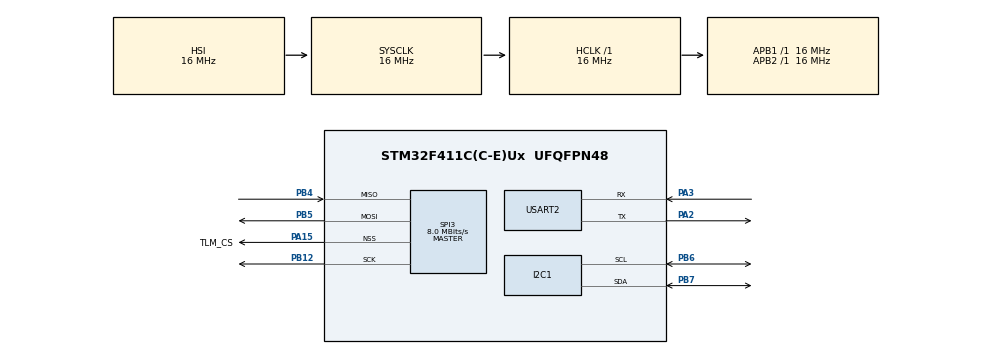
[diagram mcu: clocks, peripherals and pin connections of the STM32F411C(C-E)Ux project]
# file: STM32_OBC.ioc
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Dma.Request0=SPI3_TX
Dma.Request1=SPI3_RX
Dma.SPI3_RX.1.Direction=DMA_PERIPH_TO_MEMORY
Dma.SPI3_RX.1.FIFOMode=DMA_FIFOMODE_DISABLE
Dma.SPI3_RX.1.Instance=DMA1_Stream0
Dma.SPI3_RX.1.MemDataAlignment=DMA_MDATAALIGN_BYTE
Dma.SPI3_RX.1.MemInc=DMA_MINC_ENABLE
Dma.SPI3_RX.1.Mode=DMA_NORMAL
Dma.SPI3_RX.1.PeriphDataAlignment=DMA_PDATAALIGN_BYTE
Dma.SPI3_RX.1.PeriphInc=DMA_PINC_DISABLE
Dma.SPI3_RX.1.Priority=DMA_PRIORITY_LOW
Dma.SPI3_TX.0.Direction=DMA_MEMORY_TO_PERIPH
Dma.SPI3_TX.0.FIFOMode=DMA_FIFOMODE_DISABLE
Dma.SPI3_TX.0.Instance=DMA1_Stream5
Dma.SPI3_TX.0.MemDataAlignment=DMA_MDATAALIGN_BYTE
Dma.SPI3_TX.0.MemInc=DMA_MINC_ENABLE
Dma.SPI3_TX.0.Mode=DMA_NORMAL
Dma.SPI3_TX.0.PeriphDataAlignment=DMA_PDATAALIGN_BYTE
Dma.SPI3_TX.0.PeriphInc=DMA_PINC_DISABLE
Dma.SPI3_TX.0.Priority=DMA_PRIORITY_LOW
FREERTOS.Tasks01=defaultTask,24,512,StartDefaultTask,Default,NULL,Dynamic,NULL,NULL
Mcu.Family=STM32F4
Mcu.Name=STM32F411C(C-E)Ux
Mcu.Package=UFQFPN48
NVIC.DMA1_Stream0_IRQn=true\:5\:0\:false\:false\:true\:true\:false\:true\:true
NVIC.DMA1_Stream5_IRQn=true\:5\:0\:false\:false\:true\:true\:false\:true\:true
NVIC.PriorityGroup=NVIC_PRIORITYGROUP_4
PA15.GPIO_Label=TLM_CS
PA15.Mode=NSS_Signal_Hard_Output
PA15.Signal=SPI3_NSS
PA2.Mode=Asynchronous
PA2.Signal=USART2_TX
PA3.Mode=Asynchronous
PA3.Signal=USART2_RX
PB12.Mode=Full_Duplex_Master
PB12.Signal=SPI3_SCK
PB4.Mode=Full_Duplex_Master
PB4.Signal=SPI3_MISO
PB5.Mode=Full_Duplex_Master
PB5.Signal=SPI3_MOSI
PB6.Mode=I2C
PB6.Signal=I2C1_SCL
PB7.Mode=I2C
PB7.Signal=I2C1_SDA
ProjectManager.HeapSize=0x200
ProjectManager.StackSize=0x400
ProjectManager.TargetToolchain=STM32CubeIDE
RCC.AHBFreq_Value=16000000
RCC.APB1Freq_Value=16000000
RCC.APB2Freq_Value=16000000
RCC.CortexFreq_Value=16000000
RCC.HSE_VALUE=25000000
RCC.HSI_VALUE=16000000
RCC.LSE_VALUE=32768
RCC.SYSCLKFreq_VALUE=16000000
RCC.VCOOutputFreq_Value=192000000
SPI3.CalculateBaudRate=8.0 MBits/s
SPI3.Direction=SPI_DIRECTION_2LINES
SPI3.Mode=SPI_MODE_MASTER
SPI3.VirtualNSS=VM_NSSHARD
SPI3.VirtualType=VM_MASTER
USART2.VirtualMode=VM_ASYNC
VP_FREERTOS_VS_CMSIS_V2.Mode=CMSIS_V2
board=custom

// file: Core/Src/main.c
/* USER CODE BEGIN Header */
/**
  ******************************************************************************
  * @file           : main.c
  * @brief          : Main program body
  ******************************************************************************
  * @attention
  *
  * Copyright (c) 2026 STMicroelectronics.
  * All rights reserved.
  *
  * This software is licensed under terms that can be found in the LICENSE file
  * in the root directory of this software component.
  * If no LICENSE file comes with this software, it is provided AS-IS.
  *
  ******************************************************************************
  */
/* USER CODE END Header */
#include "main.h"
#include "cmsis_os.h"
#include "dma.h"
#include "i2c.h"
#include "spi.h"
#include "usart.h"
#include "gpio.h"

void SystemClock_Config(void);
void MX_FREERTOS_Init(void);

int main(void)
{

  /* MCU Configuration--------------------------------------------------------*/

  /* Reset of all peripherals, Initializes the Flash interface and the Systick. */
  HAL_Init();

  /* Configure the system clock */
  SystemClock_Config();

  /* Initialize all configured peripherals */
  MX_GPIO_Init();
  MX_DMA_Init();
  MX_SPI3_Init();
  MX_I2C1_Init();
  MX_USART2_UART_Init();

  /* Init scheduler */
  osKernelInitialize();  /* Call init function for freertos objects (in cmsis_os2.c) */
  MX_FREERTOS_Init();

  /* Start scheduler */
  osKernelStart();

  /* We should never get here as control is now taken by the scheduler */

  /* Infinite loop */
  while (1)
  {

  }
}

void SystemClock_Config(void)
{
  RCC_OscInitTypeDef RCC_OscInitStruct = {0};
  RCC_ClkInitTypeDef RCC_ClkInitStruct = {0};

  /** Configure the main internal regulator output voltage
  */
  __HAL_RCC_PWR_CLK_ENABLE();
  __HAL_PWR_VOLTAGESCALING_CONFIG(PWR_REGULATOR_VOLTAGE_SCALE1);

  /** Initializes the RCC Oscillators according to the specified parameters
  * in the RCC_OscInitTypeDef structure.
  */
  RCC_OscInitStruct.OscillatorType = RCC_OSCILLATORTYPE_HSI;
  RCC_OscInitStruct.HSIState = RCC_HSI_ON;
  RCC_OscInitStruct.HSICalibrationValue = RCC_HSICALIBRATION_DEFAULT;
  RCC_OscInitStruct.PLL.PLLState = RCC_PLL_NONE;
  if (HAL_RCC_OscConfig(&RCC_OscInitStruct) != HAL_OK)
  {
    Error_Handler();
  }

  /** Initializes the CPU, AHB and APB buses clocks
  */
  RCC_ClkInitStruct.ClockType = RCC_CLOCKTYPE_HCLK|RCC_CLOCKTYPE_SYSCLK
                              |RCC_CLOCKTYPE_PCLK1|RCC_CLOCKTYPE_PCLK2;
  RCC_ClkInitStruct.SYSCLKSource = RCC_SYSCLKSOURCE_HSI;
  RCC_ClkInitStruct.AHBCLKDivider = RCC_SYSCLK_DIV1;
  RCC_ClkInitStruct.APB1CLKDivider = RCC_HCLK_DIV1;
  RCC_ClkInitStruct.APB2CLKDivider = RCC_HCLK_DIV1;

  if (HAL_RCC_ClockConfig(&RCC_ClkInitStruct, FLASH_LATENCY_0) != HAL_OK)
  {
    Error_Handler();
  }
}

void Error_Handler(void)
{
  __disable_irq();
  while (1)
  {
  }
}

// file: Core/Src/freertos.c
/* USER CODE BEGIN Header */
/**
  ******************************************************************************
  * File Name          : freertos.c
  * Description        : Code for freertos applications
  ******************************************************************************
  * @attention
  *
  * Copyright (c) 2026 STMicroelectronics.
  * All rights reserved.
  *
  * This software is licensed under terms that can be found in the LICENSE file
  * in the root directory of this software component.
  * If no LICENSE file comes with this software, it is provided AS-IS.
  *
  ******************************************************************************
  */
/* USER CODE END Header */

#include "FreeRTOS.h"
#include "task.h"
#include "main.h"
#include "cmsis_os.h"

/* USER CODE BEGIN Includes */
#include "spi.h"
#include "i2c.h"

#include "telemetry_manager.h"
#include "oled_display.h"
/* USER CODE END Includes */

/* Definitions for defaultTask */
osThreadId_t defaultTaskHandle;
const osThreadAttr_t defaultTask_attributes = {
  .name = "defaultTask",
  .stack_size = 512 * 4,
  .priority = (osPriority_t) osPriorityNormal,
};

void StartDefaultTask(void *argument);

void MX_FREERTOS_Init(void); /* (MISRA C 2004 rule 8.1) */

void MX_FREERTOS_Init(void) {

  /* Create the thread(s) */
  /* creation of defaultTask */
  defaultTaskHandle = osThreadNew(StartDefaultTask, NULL, &defaultTask_attributes);

}

void StartDefaultTask(void *argument)
{
  /* USER CODE BEGIN StartDefaultTask */
	telemetry_manager_handle_t tlm_params = {
			.hspi = &hspi3,
			.cs_port = TLM_CS_GPIO_Port,
			.cs_pin = TLM_CS_Pin,
	};
	telemetry_manager_init(&tlm_params);

	oled_display_handle_t oled_param = {
			.hi2c = &hi2c1
	};
	oled_display_init(&oled_param);

  /* Infinite loop */
  for(;;)
  {
    osDelay(1);
  }
  /* USER CODE END StartDefaultTask */
}
